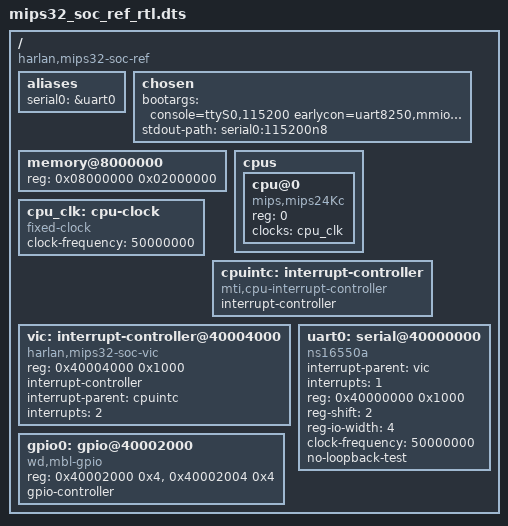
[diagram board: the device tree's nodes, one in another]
// SPDX-License-Identifier: GPL-2.0-or-later
/dts-v1/;

/ {
	#address-cells = <1>;
	#size-cells = <1>;
	compatible = "harlan,mips32-soc-ref";

	aliases { serial0 = &uart0; };
	chosen {
		/* Early MIPS ioremap uses the low physical APB alias before the
		 * kernel page tables are fully available.  The UART's normal OF
		 * resource remains 0x40000000 below; RTL maps both APB windows. */
		bootargs = "console=ttyS0,115200 earlycon=uart8250,mmio32,0x04000000 lpj=624128 rdinit=/init";
		stdout-path = "serial0:115200n8";
	};
	/* The RTL image reserves the first 8 MiB of its DDR backing store for the
	 * low-physical-address alias path and places the kernel at 0x08800000.
	 * This is an RTL-only layout; QEMU keeps its independent RAM-at-zero DTS. */
	memory@8000000 { device_type = "memory"; reg = <0x08000000 0x02000000>; };

	cpus {
		#address-cells = <1>;
		#size-cells = <0>;
		cpu@0 {
			compatible = "mips,mips24Kc";
			device_type = "cpu";
			reg = <0>;
			clocks = <&cpu_clk>;
		};
	};
	cpu_clk: cpu-clock {
		compatible = "fixed-clock";
		#clock-cells = <0>;
		clock-frequency = <50000000>;
	};
	cpuintc: interrupt-controller {
		#address-cells = <0>;
		#interrupt-cells = <1>;
		interrupt-controller;
		compatible = "mti,cpu-interrupt-controller";
	};
	vic: interrupt-controller@40004000 {
		compatible = "harlan,mips32-soc-vic";
		reg = <0x40004000 0x1000>;
		interrupt-controller;
		#interrupt-cells = <1>;
		interrupt-parent = <&cpuintc>;
		interrupts = <2>;
	};
	uart0: serial@40000000 {
		compatible = "ns16550a";
		interrupt-parent = <&vic>;
		/* UART aggregate is VIC source 1, then CPU Cause.IP2. */
		interrupts = <1>;
		reg = <0x40000000 0x1000>;
		reg-shift = <2>;
		reg-io-width = <4>;
		clock-frequency = <50000000>;
		no-loopback-test;
		status = "okay";
	};
	gpio0: gpio@40002000 {
		compatible = "wd,mbl-gpio";
		reg = <0x40002000 0x4>, <0x40002004 0x4>;
		reg-names = "dat", "dirout";
		gpio-controller;
		#gpio-cells = <2>;
		status = "okay";
	};
};
